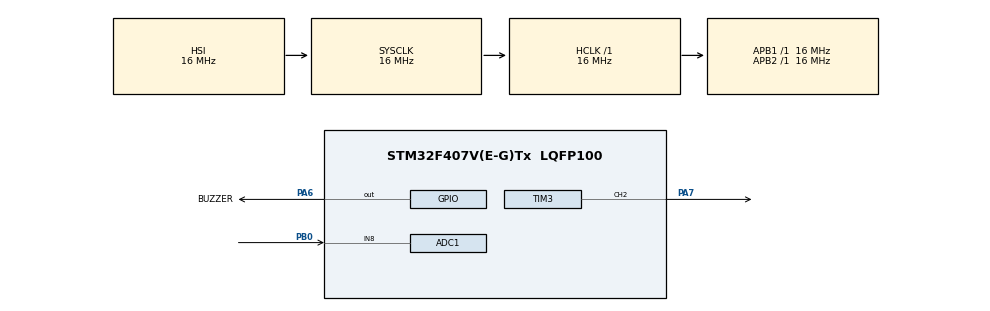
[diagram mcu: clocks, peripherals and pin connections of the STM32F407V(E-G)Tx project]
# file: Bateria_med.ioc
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ADC1.Channel-0\#ChannelRegularConversion=ADC_CHANNEL_8
ADC1.NbrOfConversionFlag=1
ADC1.Rank-0\#ChannelRegularConversion=1
ADC1.SamplingTime-0\#ChannelRegularConversion=ADC_SAMPLETIME_3CYCLES
ADC1.master=1
Dma.Request0=TIM3_CH2
Dma.TIM3_CH2.0.Direction=DMA_MEMORY_TO_PERIPH
Dma.TIM3_CH2.0.FIFOMode=DMA_FIFOMODE_DISABLE
Dma.TIM3_CH2.0.Instance=DMA1_Stream5
Dma.TIM3_CH2.0.MemDataAlignment=DMA_MDATAALIGN_WORD
Dma.TIM3_CH2.0.MemInc=DMA_MINC_ENABLE
Dma.TIM3_CH2.0.Mode=DMA_NORMAL
Dma.TIM3_CH2.0.PeriphDataAlignment=DMA_PDATAALIGN_WORD
Dma.TIM3_CH2.0.PeriphInc=DMA_PINC_DISABLE
Dma.TIM3_CH2.0.Priority=DMA_PRIORITY_HIGH
Mcu.Family=STM32F4
Mcu.Name=STM32F407V(E-G)Tx
Mcu.Package=LQFP100
NVIC.DMA1_Stream5_IRQn=true\:0\:0\:false\:false\:true\:false\:true\:true
NVIC.PriorityGroup=NVIC_PRIORITYGROUP_4
PA6.GPIO_Label=BUZZER
PA6.Signal=GPIO_Output
PA7.Signal=S_TIM3_CH2
PB0.Signal=ADCx_IN8
PH0-OSC_IN.Mode=HSE-External-Oscillator
PH0-OSC_IN.Signal=RCC_OSC_IN
PH1-OSC_OUT.Mode=HSE-External-Oscillator
PH1-OSC_OUT.Signal=RCC_OSC_OUT
ProjectManager.HeapSize=0x200
ProjectManager.StackSize=0x400
ProjectManager.TargetToolchain=STM32CubeIDE
RCC.AHBFreq_Value=16000000
RCC.APB1Freq_Value=16000000
RCC.APB2Freq_Value=16000000
RCC.CortexFreq_Value=16000000
RCC.HSE_VALUE=25000000
RCC.HSI_VALUE=16000000
RCC.LSE_VALUE=32768
RCC.SYSCLKFreq_VALUE=16000000
RCC.VCOOutputFreq_Value=192000000
SH.ADCx_IN8.0=ADC1_IN8,IN8
SH.S_TIM3_CH2.0=TIM3_CH2,PWM Generation2 CH2
TIM3.Channel-PWM\ Generation2\ CH2=TIM_CHANNEL_2
TIM3.Period=19
VP_TIM3_VS_ClockSourceINT.Mode=Internal
board=custom

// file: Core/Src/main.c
/* USER CODE BEGIN Header */
/**
  ******************************************************************************
  * @file           : main.c
  * @brief          : Main program body
  ******************************************************************************
  * @attention
  *
  * Copyright (c) 2026 STMicroelectronics.
  * All rights reserved.
  *
  * This software is licensed under terms that can be found in the LICENSE file
  * in the root directory of this software component.
  * If no LICENSE file comes with this software, it is provided AS-IS.
  *
  ******************************************************************************
  */
/* USER CODE END Header */
#include "main.h"

ADC_HandleTypeDef hadc1;

TIM_HandleTypeDef htim3;
DMA_HandleTypeDef hdma_tim3_ch2;

/* USER CODE BEGIN PV */
uint32_t pwmData[74];
float voltaje_bateria = 0.0;
uint8_t flag_bateria_baja = 0; // 0 = OK, 1 = Batería Baja

// --- TEMPORIZADORES NO BLOQUEANTES ---
uint32_t timer_lectura_adc = 0;
uint32_t timer_ritmo_alarma = 0;
uint32_t timer_frecuencia_buzzer = 0;
uint8_t estado_alarma = 0; // 0 = Silencio, 1 = Sonando
/* USER CODE END PV */

void SystemClock_Config(void);
static void MX_GPIO_Init(void);
static void MX_DMA_Init(void);
static void MX_ADC1_Init(void);
static void MX_TIM3_Init(void);

/* USER CODE BEGIN 0 */
void Set_LED_Color(uint8_t R, uint8_t G, uint8_t B) {
    uint32_t color = (G << 16) | (R << 8) | B;
    uint32_t indx = 0;
    for (int i = 23; i >= 0; i--) {
        if (color & (1 << i)) pwmData[indx] = 13;
        else pwmData[indx] = 6;
        indx++;
    }
    for (int i = 0; i < 50; i++) {
        pwmData[indx] = 0;
        indx++;
    }
    HAL_TIM_PWM_Start_DMA(&htim3, TIM_CHANNEL_2, (uint32_t *)pwmData, 74);
}

void Monitor_Bateria_NoBloqueante(void) {
    // Si ya pasó 1000 ms (1 segundo)
    if (HAL_GetTick() - timer_lectura_adc >= 1000) {
        timer_lectura_adc = HAL_GetTick();

        HAL_ADC_Start(&hadc1);
        if (HAL_ADC_PollForConversion(&hadc1, 10) == HAL_OK) {
            voltaje_bateria = HAL_ADC_GetValue(&hadc1) * 0.008864f;

            if (voltaje_bateria > 3.0 && voltaje_bateria < 6.6) {
                Set_LED_Color(255, 0, 0); // Rojo
                flag_bateria_baja = 1;    // Activar bandera
            } else if (voltaje_bateria >= 6.6) {
                Set_LED_Color(0, 255, 0); // Verde
                flag_bateria_baja = 0;
            } else {
                Set_LED_Color(0, 0, 255); // Azul
                flag_bateria_baja = 0;
            }
        }
        HAL_ADC_Stop(&hadc1);
    }
}

void Control_Buzzer_NoBloqueante(void) {
    if (flag_bateria_baja == 1) {
        // Controlar el ritmo: 200ms sonando, 200ms silencio
        if (HAL_GetTick() - timer_ritmo_alarma >= 200) {
            timer_ritmo_alarma = HAL_GetTick();
            estado_alarma = !estado_alarma;
        }

        // Si es momento de sonar
        if (estado_alarma == 1) {
            HAL_GPIO_TogglePin(GPIOA, GPIO_PIN_6);
            for(volatile int i=0; i<2000; i++); // Micro-retraso para simular la frecuencia
        } else {
            HAL_GPIO_WritePin(GPIOA, GPIO_PIN_6, GPIO_PIN_RESET);
        }
    } else {
        estado_alarma = 0;
        HAL_GPIO_WritePin(GPIOA, GPIO_PIN_6, GPIO_PIN_RESET);
    }
}
/* USER CODE END 0 */

int main(void)
{

  /* MCU Configuration--------------------------------------------------------*/

  /* Reset of all peripherals, Initializes the Flash interface and the Systick. */
  HAL_Init();

  /* Configure the system clock */
  SystemClock_Config();

  /* Initialize all configured peripherals */
  MX_GPIO_Init();
  MX_DMA_Init();
  MX_ADC1_Init();
  MX_TIM3_Init();

  /* Infinite loop */
    /* USER CODE BEGIN WHILE */
      while (1)
      {
          // Ejecutar las tareas modulares de fondo
          Monitor_Bateria_NoBloqueante();
          Control_Buzzer_NoBloqueante();

        /* USER CODE END WHILE */

    }
}

void SystemClock_Config(void)
{
  RCC_OscInitTypeDef RCC_OscInitStruct = {0};
  RCC_ClkInitTypeDef RCC_ClkInitStruct = {0};

  /** Configure the main internal regulator output voltage
  */
  __HAL_RCC_PWR_CLK_ENABLE();
  __HAL_PWR_VOLTAGESCALING_CONFIG(PWR_REGULATOR_VOLTAGE_SCALE1);

  /** Initializes the RCC Oscillators according to the specified parameters
  * in the RCC_OscInitTypeDef structure.
  */
  RCC_OscInitStruct.OscillatorType = RCC_OSCILLATORTYPE_HSI;
  RCC_OscInitStruct.HSIState = RCC_HSI_ON;
  RCC_OscInitStruct.HSICalibrationValue = RCC_HSICALIBRATION_DEFAULT;
  RCC_OscInitStruct.PLL.PLLState = RCC_PLL_NONE;
  if (HAL_RCC_OscConfig(&RCC_OscInitStruct) != HAL_OK)
  {
    Error_Handler();
  }

  /** Initializes the CPU, AHB and APB buses clocks
  */
  RCC_ClkInitStruct.ClockType = RCC_CLOCKTYPE_HCLK|RCC_CLOCKTYPE_SYSCLK
                              |RCC_CLOCKTYPE_PCLK1|RCC_CLOCKTYPE_PCLK2;
  RCC_ClkInitStruct.SYSCLKSource = RCC_SYSCLKSOURCE_HSI;
  RCC_ClkInitStruct.AHBCLKDivider = RCC_SYSCLK_DIV1;
  RCC_ClkInitStruct.APB1CLKDivider = RCC_HCLK_DIV1;
  RCC_ClkInitStruct.APB2CLKDivider = RCC_HCLK_DIV1;

  if (HAL_RCC_ClockConfig(&RCC_ClkInitStruct, FLASH_LATENCY_0) != HAL_OK)
  {
    Error_Handler();
  }
}

static void MX_ADC1_Init(void)
{

  ADC_ChannelConfTypeDef sConfig = {0};

  /** Configure the global features of the ADC (Clock, Resolution, Data Alignment and number of conversion)
  */
  hadc1.Instance = ADC1;
  hadc1.Init.ClockPrescaler = ADC_CLOCK_SYNC_PCLK_DIV2;
  hadc1.Init.Resolution = ADC_RESOLUTION_12B;
  hadc1.Init.ScanConvMode = DISABLE;
  hadc1.Init.ContinuousConvMode = DISABLE;
  hadc1.Init.DiscontinuousConvMode = DISABLE;
  hadc1.Init.ExternalTrigConvEdge = ADC_EXTERNALTRIGCONVEDGE_NONE;
  hadc1.Init.ExternalTrigConv = ADC_SOFTWARE_START;
  hadc1.Init.DataAlign = ADC_DATAALIGN_RIGHT;
  hadc1.Init.NbrOfConversion = 1;
  hadc1.Init.DMAContinuousRequests = DISABLE;
  hadc1.Init.EOCSelection = ADC_EOC_SINGLE_CONV;
  if (HAL_ADC_Init(&hadc1) != HAL_OK)
  {
    Error_Handler();
  }

  /** Configure for the selected ADC regular channel its corresponding rank in the sequencer and its sample time.
  */
  sConfig.Channel = ADC_CHANNEL_8;
  sConfig.Rank = 1;
  sConfig.SamplingTime = ADC_SAMPLETIME_3CYCLES;
  if (HAL_ADC_ConfigChannel(&hadc1, &sConfig) != HAL_OK)
  {
    Error_Handler();
  }

}

static void MX_TIM3_Init(void)
{

  TIM_ClockConfigTypeDef sClockSourceConfig = {0};
  TIM_MasterConfigTypeDef sMasterConfig = {0};
  TIM_OC_InitTypeDef sConfigOC = {0};

  htim3.Instance = TIM3;
  htim3.Init.Prescaler = 0;
  htim3.Init.CounterMode = TIM_COUNTERMODE_UP;
  htim3.Init.Period = 19;
  htim3.Init.ClockDivision = TIM_CLOCKDIVISION_DIV1;
  htim3.Init.AutoReloadPreload = TIM_AUTORELOAD_PRELOAD_DISABLE;
  if (HAL_TIM_Base_Init(&htim3) != HAL_OK)
  {
    Error_Handler();
  }
  sClockSourceConfig.ClockSource = TIM_CLOCKSOURCE_INTERNAL;
  if (HAL_TIM_ConfigClockSource(&htim3, &sClockSourceConfig) != HAL_OK)
  {
    Error_Handler();
  }
  if (HAL_TIM_PWM_Init(&htim3) != HAL_OK)
  {
    Error_Handler();
  }
  sMasterConfig.MasterOutputTrigger = TIM_TRGO_RESET;
  sMasterConfig.MasterSlaveMode = TIM_MASTERSLAVEMODE_DISABLE;
  if (HAL_TIMEx_MasterConfigSynchronization(&htim3, &sMasterConfig) != HAL_OK)
  {
    Error_Handler();
  }
  sConfigOC.OCMode = TIM_OCMODE_PWM1;
  sConfigOC.Pulse = 0;
  sConfigOC.OCPolarity = TIM_OCPOLARITY_HIGH;
  sConfigOC.OCFastMode = TIM_OCFAST_DISABLE;
  if (HAL_TIM_PWM_ConfigChannel(&htim3, &sConfigOC, TIM_CHANNEL_2) != HAL_OK)
  {
    Error_Handler();
  }
  HAL_TIM_MspPostInit(&htim3);

}

static void MX_DMA_Init(void)
{

  /* DMA controller clock enable */
  __HAL_RCC_DMA1_CLK_ENABLE();

  /* DMA interrupt init */
  /* DMA1_Stream5_IRQn interrupt configuration */
  HAL_NVIC_SetPriority(DMA1_Stream5_IRQn, 0, 0);
  HAL_NVIC_EnableIRQ(DMA1_Stream5_IRQn);

}

static void MX_GPIO_Init(void)
{
  GPIO_InitTypeDef GPIO_InitStruct = {0};

  /* GPIO Ports Clock Enable */
  __HAL_RCC_GPIOH_CLK_ENABLE();
  __HAL_RCC_GPIOA_CLK_ENABLE();
  __HAL_RCC_GPIOB_CLK_ENABLE();

  /*Configure GPIO pin Output Level */
  HAL_GPIO_WritePin(BUZZER_GPIO_Port, BUZZER_Pin, GPIO_PIN_RESET);

  /*Configure GPIO pin : BUZZER_Pin */
  GPIO_InitStruct.Pin = BUZZER_Pin;
  GPIO_InitStruct.Mode = GPIO_MODE_OUTPUT_PP;
  GPIO_InitStruct.Pull = GPIO_NOPULL;
  GPIO_InitStruct.Speed = GPIO_SPEED_FREQ_LOW;
  HAL_GPIO_Init(BUZZER_GPIO_Port, &GPIO_InitStruct);

}

void Error_Handler(void)
{
  __disable_irq();
  while (1)
  {
  }
}
